# M261_v1 register map
File version: 1.0
Registers are 32-bit, read-write, reset 0x0 unless marked. A register's access mark holds for its fields unless they carry their own. Offsets are from the block's base; [hi:lo] are bit positions; {n}, {i} and the like mark numbered series; 'fields as' and 'values as' point back to an identical list.

## SYS — SYS Register Map
Base 0x40000000
0x00 SYS_PDID ro reset 0x235100 — Part Device Identification Number Register
  [31:0] PDID — Part Device Identification Number (Read Only). This register reflects device part number code. Software can read this register to identify which device is used.
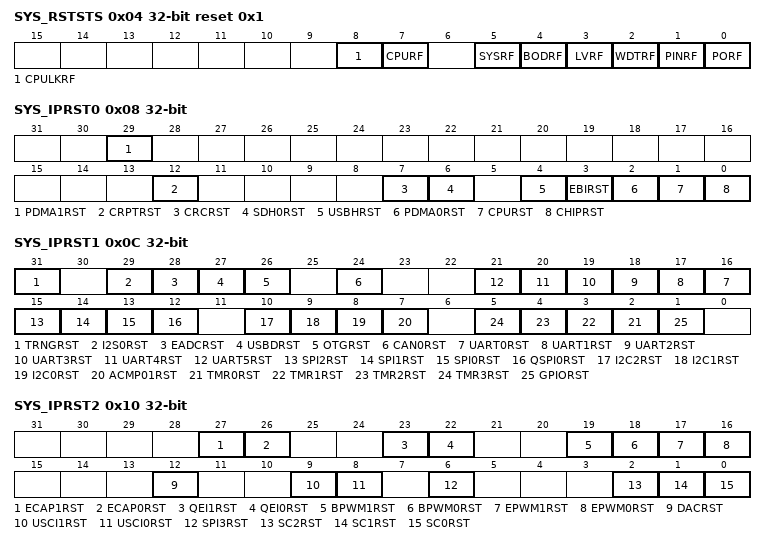
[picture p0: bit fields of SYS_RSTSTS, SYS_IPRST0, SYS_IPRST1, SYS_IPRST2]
0x04 SYS_RSTSTS reset 0x1 — System Reset Status Register
  [8] CPULKRF — CPU Lockup Reset Flag. The CPU Lockup reset flag is set by hardware if Cortex-M23 lockup happened. Note1: Write 1 to clear this bit to 0. Note2: When CPU lockup happened under ICE is connected, This flag will set to 1 but chip will not reset.
    0=No reset from CPU lockup happened; 1=The Cortex-M23 lockup happened and chip is reset
  [7] CPURF — CPU Reset Flag. The CPU reset flag is set by hardware if software writes CPURST (SYS_IPRST0[1]) 1 to reset the Cortex-M23 core and Flash Memory Controller (FMC). Note: Write 1 to clear this bit to 0.
    0=No reset from CPU; 1=The Cortex-M23 Core and FMC are reset by software setting CPURST to 1
  [5] SYSRF — System Reset Flag. The system reset flag is set by the 'Reset Signal' from the Cortex-M23 Core to indicate the previous reset source. Note: Write 1 to clear this bit to 0.
    0=No reset from the Cortex-M23; 1=The Cortex-M23 had issued the reset signal to reset the system by writing 1 to the bit SYSRESETREQ(AIRCR[2], Application Interrupt and Reset Control Register, address = 0xE000ED0C) in system control registers of Cortex-M23 core
  [4] BODRF — BOD Reset Flag. The BOD reset flag is set by the 'Reset Signal' from the Brown-out Detector to indicate the previous reset source. Note: Write 1 to clear this bit to 0.
    0=No reset from BOD; 1=The BOD had issued the reset signal to reset the system
  [3] LVRF — LVR Reset Flag. The LVR reset flag is set by the 'Reset Signal' from the Low Voltage Reset Controller to indicate the previous reset source. Note: Write 1 to clear this bit to 0.
    0=No reset from LVR; 1=LVR controller had issued the reset signal to reset the system
  [2] WDTRF — WDT Reset Flag. The WDT reset flag is set by the 'Reset Signal' from the Watchdog Timer or Window Watchdog Timer to indicate the previous reset source. Note1: Write 1 to clear this bit to 0. Note2: Watchdog Timer register RSTF(WDT_CTL[2]) bit is set if the system has been reset by WDT time-out reset. Window Watchdog Timer register WWDTRF(WWDT_STATUS[1]) bit is set if the system has been reset by WWDT time-out reset.
    0=No reset from watchdog timer or window watchdog timer; 1=The watchdog timer or window watchdog timer had issued the reset signal to reset the system
  [1] PINRF — nRESET Pin Reset Flag. The nRESET pin reset flag is set by the 'Reset Signal' from the nRESET Pin to indicate the previous reset source. Note: Write 1 to clear this bit to 0.
    0=No reset from nRESET pin; 1=Pin nRESET had issued the reset signal to reset the system
  [0] PORF — POR Reset Flag. The POR reset flag is set by the 'Reset Signal' from the Power-on Reset (POR) Controller or bit CHIPRST (SYS_IPRST0[0]) to indicate the previous reset source. Note: Write 1 to clear this bit to 0.
    0=No reset from POR or CHIPRST; 1=Power-on Reset (POR) or CHIPRST had issued the reset signal to reset the system
0x08 SYS_IPRST0 — Peripheral Reset Control Register 0
  [29] PDMA1RST — PDMA1 Controller Reset (Write Protect). Setting this bit to 1 will generate a reset signal to the PDMA1. User needs to set this bit to 0 to release from reset state. Note: This bit is write protected. Refer to the SYS_REGLCTL register.
    0=PDMA1 controller normal operation; 1=PDMA1 controller reset
  [12] CRPTRST — CRYPTO Controller Reset (Write Protect). Setting this bit to 1 will generate a reset signal to the CRYPTO controller. User needs to set this bit to 0 to release from the reset state. Note: This bit is write protected. Refer to the SYS_REGLCTL register.
    0=CRYPTO controller normal operation; 1=CRYPTO controller reset
  [7] CRCRST — CRC Calculation Controller Reset (Write Protect). Set this bit to 1 will generate a reset signal to the CRC calculation controller. User needs to set this bit to 0 to release from the reset state. Note: This bit is write protected. Refer to the SYS_REGLCTL register.
    0=CRC calculation controller normal operation; 1=CRC calculation controller reset
  [6] SDH0RST — SDHOST0 Controller Reset (Write Protect). Setting this bit to 1 will generate a reset signal to the SDHOST0 controller. User needs to set this bit to 0 to release from the reset state. Note: This bit is write protected. Refer to the SYS_REGLCTL register.
    0=SDHOST0 controller normal operation; 1=SDHOST0 controller reset
  [4] USBHRST — USB Host Controller Reset (Write Protect). Set this bit to 1 will generate a reset signal to the USB Host. User needs to set this bit to 0 to release from the reset state. Note: This bit is write protected. Refer to the SYS_REGLCTL register.
    0=USB Host controller normal operation; 1=USB Host controller reset
  [3] EBIRST — EBI Controller Reset (Write Protect). Set this bit to 1 will generate a reset signal to the EBI. User needs to set this bit to 0 to release from the reset state. Note: This bit is write protected. Refer to the SYS_REGLCTL register.
    0=EBI controller normal operation; 1=EBI controller reset
  [2] PDMA0RST — PDMA0 Controller Reset (Write Protect). Setting this bit to 1 will generate a reset signal to the PDMA0. User needs to set this bit to 0 to release from reset state. Note: This bit is write protected. Refer to the SYS_REGLCTL register.
    0=PDMA0 controller normal operation; 1=PDMA0 controller reset
  [1] CPURST — Processor Core One-shot Reset (Write Protect). Setting this bit will only reset the processor core and Flash Memory Controller(FMC), and this bit will automatically return to 0 after the 2 clock cycles. Note: This bit is write protected. Refer to the SYS_REGLCTL register.
    0=Processor core normal operation; 1=Processor core one-shot reset
  [0] CHIPRST — Chip One-shot Reset (Write Protect). Setting this bit will reset the whole chip, including Processor core and all peripherals, and this bit will automatically return to 0 after the 2 clock cycles. The CHIPRST is same as the POR reset, all the chip controllers is reset and the chip setting from Flash are also reload. About the difference between CHIPRST and SYSRESETREQ(AIRCR[2]), please refer to section 6.2.2. Note: This bit is write protected. Refer to the SYS_REGLCTL register.
    0=Chip normal operation; 1=Chip one-shot reset
0x0C SYS_IPRST1 — Peripheral Reset Control Register 1
  [31] TRNGRST — TRNG Controller Reset
    0=TRNG controller normal operation; 1=TRNG controller reset
  [29] I2S0RST — I2S0 Controller Reset
    0=I2S0 controller normal operation; 1=I2S0 controller reset
  [28] EADCRST — EADC Controller Reset
    0=EADC controller normal operation; 1=EADC controller reset
  [27] USBDRST — USBD Controller Reset
    0=USBD controller normal operation; 1=USBD controller reset
  [26] OTGRST — OTG Controller Reset
    0=OTG controller normal operation; 1=OTG controller reset
  [24] CAN0RST — CAN0 Controller Reset
    0=CAN0 controller normal operation; 1=CAN0 controller reset
  [n+16] UART{n}RST (n=0..5) — UART{n} Controller Reset
    0=UART{n} controller normal operation; 1=UART{n} controller reset
  [15] SPI2RST — SPI2 Controller Reset
    0=SPI2 controller normal operation; 1=SPI2 controller reset
  [14] SPI1RST — SPI1 Controller Reset
    0=SPI1 controller normal operation; 1=SPI1 controller reset
  [13] SPI0RST — SPI0 Controller Reset
    0=SPI0 controller normal operation; 1=SPI0 controller reset
  [12] QSPI0RST — QSPI0 Controller Reset
    0=QSPI0 controller normal operation; 1=QSPI0 controller reset
  [10] I2C2RST — I2C2 Controller Reset
    0=I2C2 controller normal operation; 1=I2C2 controller reset
  [9] I2C1RST — I2C1 Controller Reset
    0=I2C1 controller normal operation; 1=I2C1 controller reset
  [8] I2C0RST — I2C0 Controller Reset
    0=I2C0 controller normal operation; 1=I2C0 controller reset
  [7] ACMP01RST — Analog Comparator 0/1 Controller Reset
    0=Analog Comparator 0/1 controller normal operation; 1=Analog Comparator 0/1 controller reset
  [n+2] TMR{n}RST (n=0..3) — Timer{n} Controller Reset
    0=Timer{n} controller normal operation; 1=Timer{n} controller reset
  [1] GPIORST — GPIO Controller Reset
    0=GPIO controller normal operation; 1=GPIO controller reset
0x10 SYS_IPRST2 — Peripheral Reset Control Register 2
  [27] ECAP1RST — ECAP1 Controller Reset
    0=ECAP1 controller normal operation; 1=ECAP1 controller reset
  [26] ECAP0RST — ECAP0 Controller Reset
    0=ECAP0 controller normal operation; 1=ECAP0 controller reset
  [23] QEI1RST — QEI1 Controller Reset
    0=QEI1 controller normal operation; 1=QEI1 controller reset
  [22] QEI0RST — QEI0 Controller Reset
    0=QEI0 controller normal operation; 1=QEI0 controller reset
  [19] BPWM1RST — BPWM1 Controller Reset
    0=BPWM1 controller normal operation; 1=BPWM1 controller reset
  [18] BPWM0RST — BPWM0 Controller Reset
    0=BPWM0 controller normal operation; 1=BPWM0 controller reset
  [17] EPWM1RST — EPWM1 Controller Reset
    0=EPWM1 controller normal operation; 1=EPWM1 controller reset
  [16] EPWM0RST — EPWM0 Controller Reset
    0=EPWM0 controller normal operation; 1=EPWM0 controller reset
  [12] DACRST — DAC Controller Reset
    0=DAC controller normal operation; 1=DAC controller reset
  [9] USCI1RST — USCI1 Controller Reset
    0=USCI1 controller normal operation; 1=USCI1 controller reset
  [8] USCI0RST — USCI0 Controller Reset
    0=USCI0 controller normal operation; 1=USCI0 controller reset
  [6] SPI3RST — SPI3 Controller Reset
    0=SPI3 controller normal operation; 1=SPI3 controller reset
  [2] SC2RST — SC2 Controller Reset
    0=SC2 controller normal operation; 1=SC2 controller reset
  [1] SC1RST — SC1 Controller Reset
    0=SC1 controller normal operation; 1=SC1 controller reset
  [0] SC0RST — SC0 Controller Reset
    0=SC0 controller normal operation; 1=SC0 controller reset
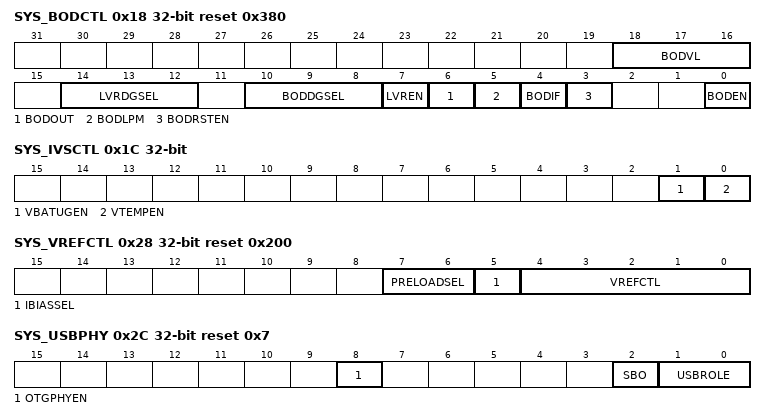
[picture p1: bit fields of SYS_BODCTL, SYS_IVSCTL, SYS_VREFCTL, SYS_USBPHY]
0x18 SYS_BODCTL reset 0x380 (reset mask 0xFFF0FFF0) — Brown-out Detector Control Register
  [18:16] BODVL — Brown-out Detector Threshold Voltage Selection (Write Protect). The default value is set by Flash controller user configuration register CBOV (CONFIG0 [23:21]). Note: These bits are write protected. Refer to the SYS_REGLCTL register.
    0=Brown-out Detector threshold voltage is 1.6V; 1=Brown-out Detector threshold voltage is 1.8V; 2=Brown-out Detector threshold voltage is 2.0V; 3=Brown-out Detector threshold voltage is 2.2V; 4=Brown-out Detector threshold voltage is 2.4V; 5=Brown-out Detector threshold voltage is 2.6V; 6=Brown-out Detector threshold voltage is 2.8V; 7=Brown-out Detector threshold voltage is 3.0V
  [14:12] LVRDGSEL — LVR Output De-glitch Time Select (Write Protect). Note: These bits are write protected. Refer to the SYS_REGLCTL register.
    0=Without de-glitch function; 1=4 system clock (HCLK); 2=8 system clock (HCLK); 3=16 system clock (HCLK); 4=32 system clock (HCLK); 5=64 system clock (HCLK); 6=128 system clock (HCLK); 7=256 system clock (HCLK)
  [10:8] BODDGSEL — Brown-out Detector Output De-glitch Time Select (Write Protect). Note: These bits are write protected. Refer to the SYS_REGLCTL register.
    0=BOD output is sampled by LIRC clock; 1=4 system clock (HCLK); 2=8 system clock (HCLK); 3=16 system clock (HCLK); 4=32 system clock (HCLK); 5=64 system clock (HCLK); 6=128 system clock (HCLK); 7=256 system clock (HCLK)
  [7] LVREN — Low Voltage Reset Enable Bit (Write Protect). The LVR function resets the chip when the input power voltage is lower than LVR circuit setting. LVR function is enabled by default. Note1: After enabling the bit, the LVR function will be active with 200us delay for LVR output stable (default). Note2: This bit is write protected. Refer to the SYS_REGLCTL register.
    0=Low Voltage Reset function Disabled; 1=Low Voltage Reset function Enabled
  [6] BODOUT — Brown-out Detector Output Status. It means the detected voltage is lower than BODVL setting. If the BODEN is 0, BOD function disabled, this bit always responds 0.
    0=Brown-out Detector output status is 0; 1=Brown-out Detector output status is 1
  [5] BODLPM — Brown-out Detector Low Power Mode (Write Protect). Note1: The BOD consumes about 100uA in normal mode, the low power mode can reduce the current to about 1/10 but slow the BOD response. Note2: This bit is write protected. Refer to the SYS_REGLCTL register.
    0=BOD operate in normal mode (default); 1=BOD Low Power mode Enabled
  [4] BODIF — Brown-out Detector Interrupt Flag. Note: Write 1 to clear this bit to 0.
    0=Brown-out Detector does not detect any voltage draft at VDD down through or up through the voltage of BODVL setting; 1=When Brown-out Detector detects the VDD is dropped down through the voltage of BODVL setting or the VDD is raised up through the voltage of BODVL setting, this bit is set to 1 and the brown-out interrupt is requested if brown-out interrupt is enabled
  [3] BODRSTEN — Brown-out Reset Enable Bit (Write Protect). The default value is set by Flash controller user configuration register CBORST(CONFIG0[20]) bit . Note1: While the Brown-out Detector function is enabled (BODEN high) and BOD reset function is enabled (BODRSTEN high), BOD will assert a signal to reset chip when the detected voltage is lower than the threshold (BODOUT high). While the BOD function is enabled (BODEN high) and BOD interrupt function is enabled (BODRSTEN low), BOD will assert an interrupt if AVDD.than BODVL, BOD interrupt will keep till to the BODIF set to 0. BOD interrupt can be blocked by disabling the NVIC BOD interrupt or disabling BOD function (set BODEN low). Note2: This bit is write protected. Refer to the SYS_REGLCTL register.
    0=Brown-out 'INTERRUPT' function Enabled; 1=Brown-out 'RESET' function Enabled
  [0] BODEN — Brown-out Detector Enable Bit (Write Protect). The default value is set by Flash controller user configuration register CBODEN (CONFIG0 [23]). Note: This bit is write protected. Refer to the SYS_REGLCTL register.
    0=Brown-out Detector function Disabled; 1=Brown-out Detector function Enabled
0x1C SYS_IVSCTL — Internal Voltage Source Control Register
  [1] VBATUGEN — VBAT Unity Gain Buffer Enable Bit. This bit is used to enable/disable VBAT unity gain buffer function. Note: After this bit is set to 1, the value of VBAT unity gain buffer output voltage can be obtained from ADC conversion result.
    0=VBAT unity gain buffer function Disabled (default); 1=VBAT unity gain buffer function Enabled
  [0] VTEMPEN — Temperature Sensor Enable Bit. This bit is used to enable/disable temperature sensor function. Note: After this bit is set to 1, the value of temperature sensor output can be obtained from ADC conversion result. Please refer to ADC function chapter for details.
    0=Temperature sensor function Disabled (default); 1=Temperature sensor function Enabled
0x24 SYS_PORCTL0 (reset mask 0xFFFFFF00) — Power-on Reset Controller Register 0
  [15:0] PORMASK — Power-on Reset Mask Enable Bit (Write Protect). When powered on, the POR circuit generates a reset signal to reset the whole chip function, but noise on the power may cause the POR active again. User can mask internal POR signal to avoid unpredictable noise to cause chip reset by writing 0x5AA5 to this field. The POR function will be active again when this field is set to another value or chip is reset by other reset source, including: nRESET, Watchdog, LVR reset, BOD reset, ICE reset command and the software-chip reset function. Note: These bits are write protected. Refer to the SYS_REGLCTL register.
0x28 SYS_VREFCTL reset 0x200 — VREF Control Register
  [7:6] PRELOADSEL — Pre-load Timing Selection (Write Protect). Note: These bits is write protected. Refer to the SYS_REGLCTL register.
    0=pre-load time is 60us for 0.1uF Capacitor; 1=pre-load time is 310us for 1uF Capacitor; 2=pre-load time is 2100us for 4.7uF Capacitor; 3=pre-load time is 2850us for 10uF Capacitor
  [5] IBIASSEL — VREF Bias Current Selection (Write Protect). Note: This bit is write protected. Refer to the SYS_REGLCTL register.
    0=Bias current from MEGBIAS; 1=Bias current from internal
  [4:0] VREFCTL — VREF Control Bits (Write Protect). Note: These bits are write protected. Refer to the SYS_REGLCTL register.
    0=VREF is from external pin; 3=VREF is internal 1.6V; 7=VREF is internal 2.0V; 11=VREF is internal 2.5V; 15=VREF is internal 3.0V
0x2C SYS_USBPHY reset 0x7 — USB PHY Control Register
  [8] OTGPHYEN — USB OTG PHY Enable. This bit is used to enable/disable OTG PHY function.
    0=OTG PHY function Disabled (default); 1=OTG PHY function Enabled
  [2] SBO — Note: This bit must always be kept 1. If set to 0, the result is unpredictable.
  [1:0] USBROLE — USB Role Option (Write Protect). These two bits are used to select the role of USB. Note: These bits are write protected. Refer to the SYS_REGLCTL register.
    0=Standard USB Device mode; 1=Standard USB Host mode; 2=ID dependent mode; 3=On-The-Go device mode (default)
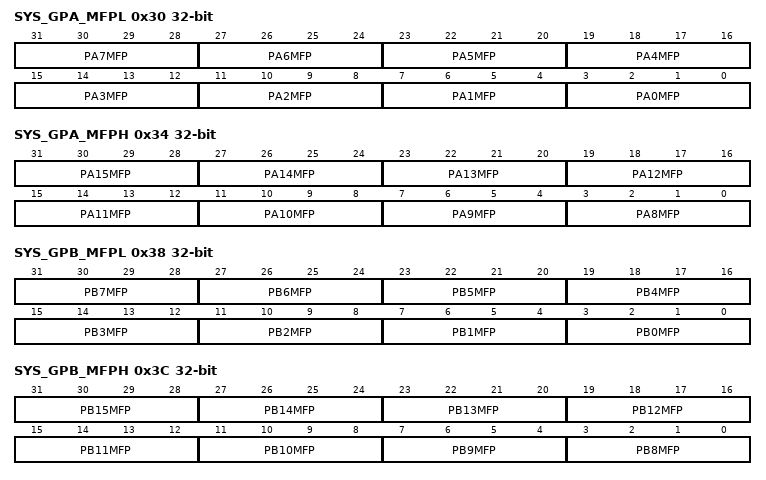
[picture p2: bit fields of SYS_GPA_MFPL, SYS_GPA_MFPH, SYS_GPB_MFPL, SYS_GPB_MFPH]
0x30 SYS_GPA_MFPL — GPIOA Low Byte Multiple Function Control Register
  [31:28] PA7MFP — PA.7 Multi-function Pin Selection
  [27:24] PA6MFP — PA.6 Multi-function Pin Selection
  [23:20] PA5MFP — PA.5 Multi-function Pin Selection
  [19:16] PA4MFP — PA.4 Multi-function Pin Selection
  [15:12] PA3MFP — PA.3 Multi-function Pin Selection
  [11:8] PA2MFP — PA.2 Multi-function Pin Selection
  [7:4] PA1MFP — PA.1 Multi-function Pin Selection
  [3:0] PA0MFP — PA.0 Multi-function Pin Selection
0x34 SYS_GPA_MFPH — GPIOA High Byte Multiple Function Control Register
  [31:28] PA15MFP — PA.15 Multi-function Pin Selection
  [27:24] PA14MFP — PA.14 Multi-function Pin Selection
  [23:20] PA13MFP — PA.13 Multi-function Pin Selection
  [19:16] PA12MFP — PA.12 Multi-function Pin Selection
  [15:12] PA11MFP — PA.11 Multi-function Pin Selection
  [11:8] PA10MFP — PA.10 Multi-function Pin Selection
  [7:4] PA9MFP — PA.9 Multi-function Pin Selection
  [3:0] PA8MFP — PA.8 Multi-function Pin Selection
0x38 SYS_GPB_MFPL — GPIOB Low Byte Multiple Function Control Register
  [31:28] PB7MFP — PB.7 Multi-function Pin Selection
  [27:24] PB6MFP — PB.6 Multi-function Pin Selection
  [23:20] PB5MFP — PB.5 Multi-function Pin Selection
  [19:16] PB4MFP — PB.4 Multi-function Pin Selection
  [15:12] PB3MFP — PB.3 Multi-function Pin Selection
  [11:8] PB2MFP — PB.2 Multi-function Pin Selection
  [7:4] PB1MFP — PB.1 Multi-function Pin Selection
  [3:0] PB0MFP — PB.0 Multi-function Pin Selection
0x3C SYS_GPB_MFPH — GPIOB High Byte Multiple Function Control Register
  [31:28] PB15MFP — PB.15 Multi-function Pin Selection
  [27:24] PB14MFP — PB.14 Multi-function Pin Selection
  [23:20] PB13MFP — PB.13 Multi-function Pin Selection
  [19:16] PB12MFP — PB.12 Multi-function Pin Selection
  [15:12] PB11MFP — PB.11 Multi-function Pin Selection
  [11:8] PB10MFP — PB.10 Multi-function Pin Selection
  [7:4] PB9MFP — PB.9 Multi-function Pin Selection
  [3:0] PB8MFP — PB.8 Multi-function Pin Selection
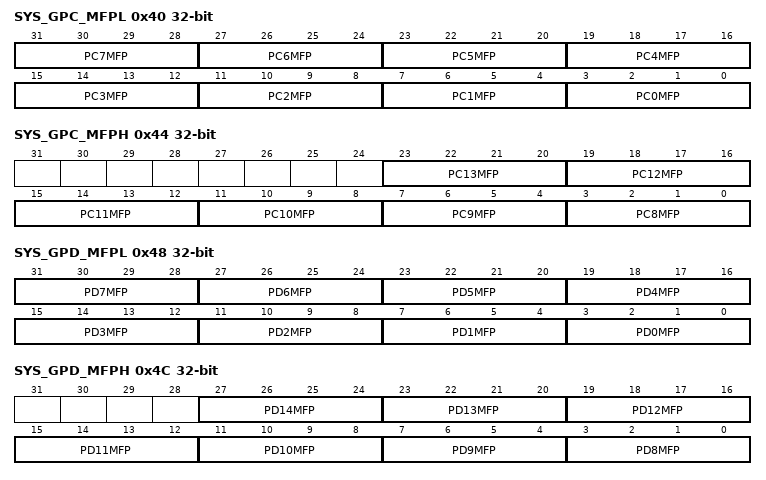
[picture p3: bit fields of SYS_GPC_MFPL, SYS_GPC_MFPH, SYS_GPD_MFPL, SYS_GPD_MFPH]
0x40 SYS_GPC_MFPL — GPIOC Low Byte Multiple Function Control Register
  [31:28] PC7MFP — PC.7 Multi-function Pin Selection
  [27:24] PC6MFP — PC.6 Multi-function Pin Selection
  [23:20] PC5MFP — PC.5 Multi-function Pin Selection
  [19:16] PC4MFP — PC.4 Multi-function Pin Selection
  [15:12] PC3MFP — PC.3 Multi-function Pin Selection
  [11:8] PC2MFP — PC.2 Multi-function Pin Selection
  [7:4] PC1MFP — PC.1 Multi-function Pin Selection
  [3:0] PC0MFP — PC.0 Multi-function Pin Selection
0x44 SYS_GPC_MFPH — GPIOC High Byte Multiple Function Control Register
  [23:20] PC13MFP — PC.13 Multi-function Pin Selection
  [19:16] PC12MFP — PC.12 Multi-function Pin Selection
  [15:12] PC11MFP — PC.11 Multi-function Pin Selection
  [11:8] PC10MFP — PC.10 Multi-function Pin Selection
  [7:4] PC9MFP — PC.9 Multi-function Pin Selection
  [3:0] PC8MFP — PC.8 Multi-function Pin Selection
0x48 SYS_GPD_MFPL — GPIOD Low Byte Multiple Function Control Register
  [31:28] PD7MFP — PD.7 Multi-function Pin Selection
  [27:24] PD6MFP — PD.6 Multi-function Pin Selection
  [23:20] PD5MFP — PD.5 Multi-function Pin Selection
  [19:16] PD4MFP — PD.4 Multi-function Pin Selection
  [15:12] PD3MFP — PD.3 Multi-function Pin Selection
  [11:8] PD2MFP — PD.2 Multi-function Pin Selection
  [7:4] PD1MFP — PD.1 Multi-function Pin Selection
  [3:0] PD0MFP — PD.0 Multi-function Pin Selection
0x4C SYS_GPD_MFPH — GPIOD High Byte Multiple Function Control Register
  [27:24] PD14MFP — PD.14 Multi-function Pin Selection
  [23:20] PD13MFP — PD.13 Multi-function Pin Selection
  [19:16] PD12MFP — PD.12 Multi-function Pin Selection
  [15:12] PD11MFP — PD.11 Multi-function Pin Selection
  [11:8] PD10MFP — PD.10 Multi-function Pin Selection
  [7:4] PD9MFP — PD.9 Multi-function Pin Selection
  [3:0] PD8MFP — PD.8 Multi-function Pin Selection
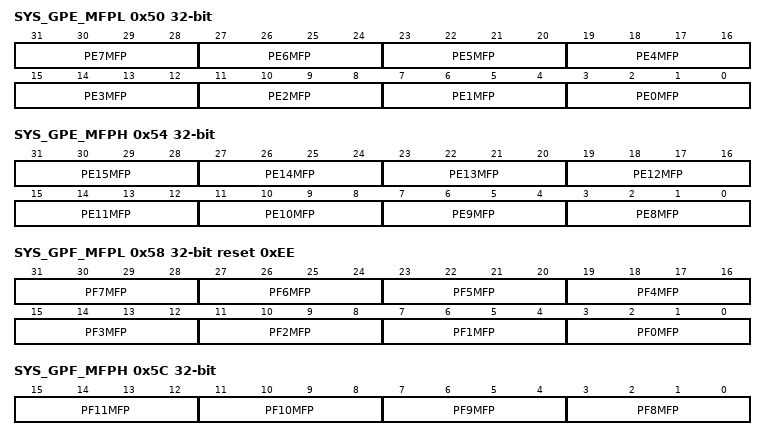
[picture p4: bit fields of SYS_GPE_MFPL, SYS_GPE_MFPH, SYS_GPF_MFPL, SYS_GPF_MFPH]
0x50 SYS_GPE_MFPL — GPIOE Low Byte Multiple Function Control Register
  [31:28] PE7MFP — PE.7 Multi-function Pin Selection
  [27:24] PE6MFP — PE.6 Multi-function Pin Selection
  [23:20] PE5MFP — PE.5 Multi-function Pin Selection
  [19:16] PE4MFP — PE.4 Multi-function Pin Selection
  [15:12] PE3MFP — PE.3 Multi-function Pin Selection
  [11:8] PE2MFP — PE.2 Multi-function Pin Selection
  [7:4] PE1MFP — PE.1 Multi-function Pin Selection
  [3:0] PE0MFP — PE.0 Multi-function Pin Selection
0x54 SYS_GPE_MFPH — GPIOE High Byte Multiple Function Control Register
  [31:28] PE15MFP — PE.15 Multi-function Pin Selection
  [27:24] PE14MFP — PE.14 Multi-function Pin Selection
  [23:20] PE13MFP — PE.13 Multi-function Pin Selection
  [19:16] PE12MFP — PE.12 Multi-function Pin Selection
  [15:12] PE11MFP — PE.11 Multi-function Pin Selection
  [11:8] PE10MFP — PE.10 Multi-function Pin Selection
  [7:4] PE9MFP — PE.9 Multi-function Pin Selection
  [3:0] PE8MFP — PE.8 Multi-function Pin Selection
0x58 SYS_GPF_MFPL reset 0xEE — GPIOF Low Byte Multiple Function Control Register
  [31:28] PF7MFP — PF.7 Multi-function Pin Selection
  [27:24] PF6MFP — PF.6 Multi-function Pin Selection
  [23:20] PF5MFP — PF.5 Multi-function Pin Selection
  [19:16] PF4MFP — PF.4 Multi-function Pin Selection
  [15:12] PF3MFP — PF.3 Multi-function Pin Selection
  [11:8] PF2MFP — PF.2 Multi-function Pin Selection
  [7:4] PF1MFP — PF.1 Multi-function Pin Selection
  [3:0] PF0MFP — PF.0 Multi-function Pin Selection
0x5C SYS_GPF_MFPH — GPIOF High Byte Multiple Function Control Register
  [15:12] PF11MFP — PF.11 Multi-function Pin Selection
  [11:8] PF10MFP — PF.10 Multi-function Pin Selection
  [7:4] PF9MFP — PF.9 Multi-function Pin Selection
  [3:0] PF8MFP — PF.8 Multi-function Pin Selection
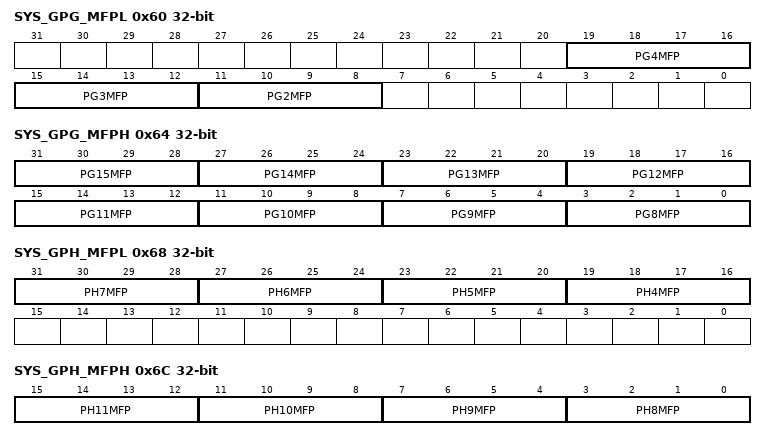
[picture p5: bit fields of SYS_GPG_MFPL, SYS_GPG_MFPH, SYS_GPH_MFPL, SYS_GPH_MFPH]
0x60 SYS_GPG_MFPL — GPIOG Low Byte Multiple Function Control Register
  [19:16] PG4MFP — PG.4 Multi-function Pin Selection
  [15:12] PG3MFP — PG.3 Multi-function Pin Selection
  [11:8] PG2MFP — PG.2 Multi-function Pin Selection
0x64 SYS_GPG_MFPH — GPIOG High Byte Multiple Function Control Register
  [31:28] PG15MFP — PG.15 Multi-function Pin Selection
  [27:24] PG14MFP — PG.14 Multi-function Pin Selection
  [23:20] PG13MFP — PG.13 Multi-function Pin Selection
  [19:16] PG12MFP — PG.12 Multi-function Pin Selection
  [15:12] PG11MFP — PG.11 Multi-function Pin Selection
  [11:8] PG10MFP — PG.10 Multi-function Pin Selection
  [7:4] PG9MFP — PG.9 Multi-function Pin Selection
  [3:0] PG8MFP — PG.8 Multi-function Pin Selection
0x68 SYS_GPH_MFPL — GPIOH Low Byte Multiple Function Control Register
  [31:28] PH7MFP — PH.7 Multi-function Pin Selection
  [27:24] PH6MFP — PH.6 Multi-function Pin Selection
  [23:20] PH5MFP — PH.5 Multi-function Pin Selection
  [19:16] PH4MFP — PH.4 Multi-function Pin Selection
0x6C SYS_GPH_MFPH — GPIOH High Byte Multiple Function Control Register
  [15:12] PH11MFP — PH.11 Multi-function Pin Selection
  [11:8] PH10MFP — PH.10 Multi-function Pin Selection
  [7:4] PH9MFP — PH.9 Multi-function Pin Selection
  [3:0] PH8MFP — PH.8 Multi-function Pin Selection
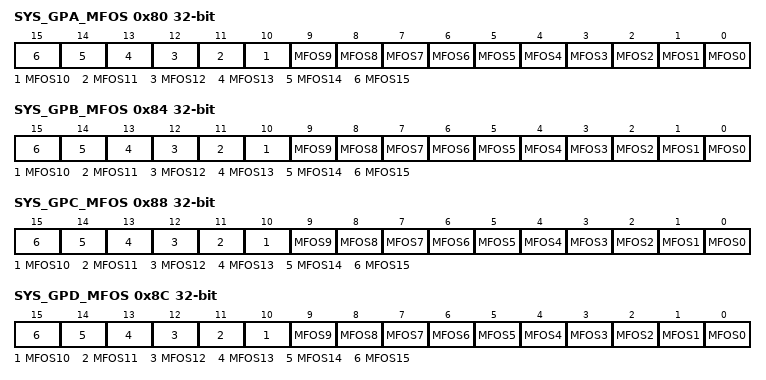
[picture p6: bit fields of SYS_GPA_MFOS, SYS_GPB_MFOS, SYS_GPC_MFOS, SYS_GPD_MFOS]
0x80 SYS_GPA_MFOS — GPIOA Multiple Function Output Select Register
  [all] fields
    0=Multiple funtion pin output mode type is Push-pull mode; 1=Multiple funtion pin output mode type is Open-drain mode
  [n] MFOS{n} (n=0..15) — GPIOA-h Pin[n] Multiple Function Pin Output Mode Select. This bit used to select multiple function pin output mode type for Px.n pin
0x84 SYS_GPB_MFOS — GPIOB Multiple Function Output Select Register
  fields as SYS_GPA_MFOS
0x88 SYS_GPC_MFOS — GPIOC Multiple Function Output Select Register
  fields as SYS_GPA_MFOS
0x8C SYS_GPD_MFOS — GPIOD Multiple Function Output Select Register
  fields as SYS_GPA_MFOS
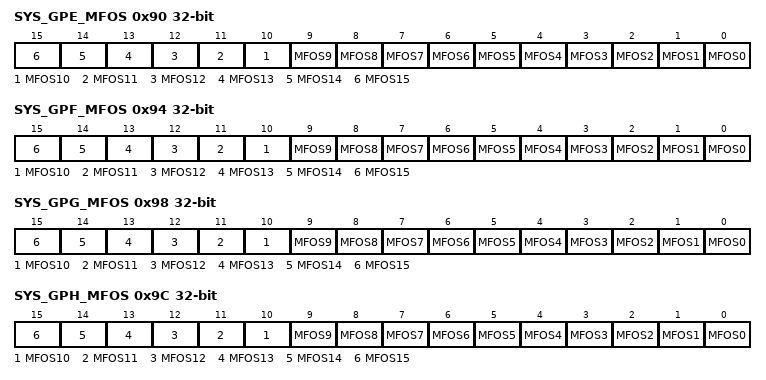
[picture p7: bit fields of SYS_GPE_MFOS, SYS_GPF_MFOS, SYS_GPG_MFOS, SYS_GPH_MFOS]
0x90 SYS_GPE_MFOS — GPIOE Multiple Function Output Select Register
  fields as SYS_GPA_MFOS
0x94 SYS_GPF_MFOS — GPIOF Multiple Function Output Select Register
  fields as SYS_GPA_MFOS
0x98 SYS_GPG_MFOS — GPIOG Multiple Function Output Select Register
  fields as SYS_GPA_MFOS
0x9C SYS_GPH_MFOS — GPIOH Multiple Function Output Select Register
  fields as SYS_GPA_MFOS
0xC0 SYS_SRAMICTL — System SRAM Interrupt Enable Control Register
  [0] PERRIEN — SRAM Parity Check Error Interrupt Enable Bit
    0=SRAM parity check error interrupt Disabled; 1=SRAM parity check error interrupt Enabled
0xC4 SYS_SRAMSTS ro — System SRAM Parity Error Status Register
  [0] PERRIF — SRAM Parity Check Error Flag. This bit indicates the System SRAM parity error occurred. Write 1 to clear this to 0.
    0=No System SRAM parity error; 1=System SRAM parity error occur
0xC8 SYS_SRAMEADR ro — System SRAM Parity Check Error Address Register
  [31:0] ERRADDR — System SRAM Parity Error Address. This register shows system SRAM parity error byte address.
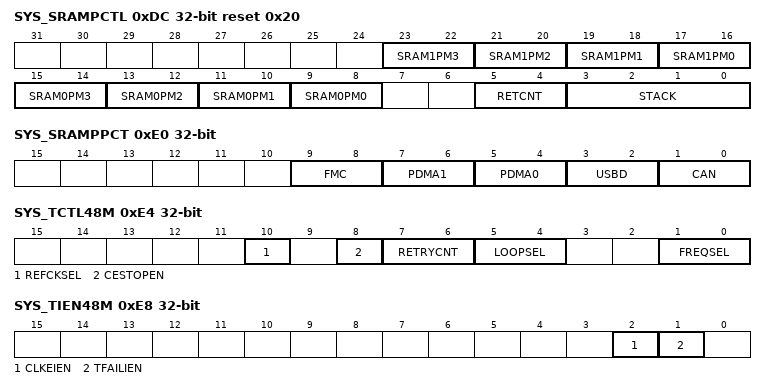
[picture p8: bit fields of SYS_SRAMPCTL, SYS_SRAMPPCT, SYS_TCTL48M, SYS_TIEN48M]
0xDC SYS_SRAMPCTL reset 0x20 — System SRAM Power Mode Control Register
  [23:22] SRAM1PM3 — Bank1 SRAM Power Mode Select 3 (Write Protect). This field can control bank1 SRAM (64 KB) power mode when system enters Power-down mode for range 0x2001_4000 - 0x2001_7FFF. Note1: Bank 1 SRAM is always operating in power shut down mode for system enter Standby Power-down Mode (SPD) and Deep Power-down Mode (DPD). Note2: These bits are write protected. Refer to the SYS_REGLCTL register.
    0=Normal mode; 1=Retention mode; 2=Power shut down mode
  [21:20] SRAM1PM2 — Bank1 SRAM Power Mode Select 2 (Write Protect). This field can control bank1 SRAM (64 KB) power mode when system enters Power-down mode for range 0x2001_0000 - 0x2001_3FFF. Note1: Bank 1 SRAM is always operating in power shut down mode for system enter Standby Power-down Mode (SPD) and Deep Power-down Mode (DPD). Note2: These bits are write protected. Refer to the SYS_REGLCTL register.
    0=Normal mode; 1=Retention mode; 2=Power shut down mode
  [19:18] SRAM1PM1 — Bank1 SRAM Power Mode Select 1 (Write Protect). This field can control bank1 SRAM (64 KB) power mode when system enters Power-down mode for range 0x2000_C000 - 0x2000_FFFF. Note1: Bank 1 SRAM is always operating in power shut down mode for system enter StandbyPower-down Mode (SPD) and Deep Power-down Mode (DPD). Note2: These bits are write protected. Refer to the SYS_REGLCTL register.
    0=Normal mode; 1=Retention mode; 2=Power shut down mode
  [17:16] SRAM1PM0 — Bank1 SRAM Power Mode Select 0 (Write Protect). This field can control bank1 SRAM (64 KB) power mode when system enters Power-down mode for range 0x2000_8000 - 0x2000_BFFF. Note1: Bank 1 SRAM is always operating in power shut down mode for system enter StandbyPower-down Mode (SPD) and Deep Power-down Mode (DPD). Note2: These bits are write protected. Refer to the SYS_REGLCTL register.
    0=Normal mode; 1=Retention mode; 2=Power shut down mode
  [15:14] SRAM0PM3 — Bank0 SRAM Power Mode Select 3 (Write Protect). This field can control bank0 SRAM (32 KB) power mode when system enters Power-down mode for range 0x2006_0000 - 0x2000_7FFF. Note1: Bank 0 SRAM is always operating in power shut down mode for system enter Deep Power-down Mode (DPD). Note2: These bits are write protected. Refer to the SYS_REGLCTL register.
    0=Normal mode; 1=Retention mode; 2=Power shut down mode
  [13:12] SRAM0PM2 — Bank0 SRAM Power Mode Select 2 (Write Protect). This field can control bank0 SRAM (32 KB) power mode when system enters Power-down mode for range 0x2004_0000 - 0x2000_5FFF. Note1: Bank 0 SRAM is always operating in power shut down mode for system enter Deep Power-down Mode (DPD). Note2: These bits are write protected. Refer to the SYS_REGLCTL register.
    0=Normal mode; 1=Retention mode; 2=Power shut down mode
  [11:10] SRAM0PM1 — Bank0 SRAM Power Mode Select 1 (Write Protect). This field can control bank0 sram (32k) power mode when system enters Power-down mode for range 0x2000_2000 - 0x2000_3FFF. Note1: Bank 0 SRAM is always operating in power shut down mode for system enter Deep Power-down Mode (DPD). Note2: These bits are write protected. Refer to the SYS_REGLCTL register.
    0=Normal mode; 1=Retention mode; 2=Power shut down mode
  [9:8] SRAM0PM0 — Bank0 SRAM Power Mode Select 0 (Write Protect). This field can control bank0 SRAM (32 KB) power mode when system enters Power-down mode for range 0x2000_0000 - 0x2000_1FFF. Note1: Bank 0 SRAM is always operating in power shut down mode for system enter Deep Power-down Mode (DPD). Note2: These bits are write protected. Refer to the SYS_REGLCTL register.
    0=Normal mode; 1=Retention mode; 2=Power shut down mode
  [5:4] RETCNT — SRAM Retention Count (Write Protect). This field can configure SRAM marco retention time in unit of HIRC period. Note: These bits are write protected. Refer to the SYS_REGLCTL register.
    0=one HIRC period; 1=two HIRC periods; 2=three HIRC periods; 3=four HIRC periods
  [3:0] STACK — System SRAM Stack Position (Write Protect). This field must configure the system SRAM marco that first SRAM address accessed by CPU in power-on process. Note: These bits are write protected. Refer to the SYS_REGLCTL register.
0xE0 SYS_SRAMPPCT — Peripheral SRAM Power Mode Control Register
  [all] fields
    0=Normal mode; 1=Retention mode; 2=Power shut down mode
  [9:8] FMC — FMC SRAM Power Mode Select (Write Protect). This field can control FMC cache SRAM power mode for system enter Power-down mode. Note1: Peripheral SRAM is always operating in power shut down mode for system enter Standby Power-down Mode (SPD) and Deep Power-down Mode (DPD). Note2: These bits are write protected. Refer to the SYS_REGLCTL register.
  [7:6] PDMA1 — PDMA SRAM Power Mode Select (Write Protect). This field can control PDMA1 SRAM power mode for system enter Power-down mode. Note1: Peripheral SRAM is always operating in power shut down mode for system enter Standby Power-down Mode (SPD) and Deep Power-down Mode (DPD). Note2: These bits are write protected. Refer to the SYS_REGLCTL register.
  [5:4] PDMA0 — PDMA SRAM Power Mode Select (Write Protect). This field can control PDMA0 SRAM power mode for system enter Power-down mode. Note1: Peripheral SRAM is always operating in power shut down mode for system enter Standby Power-down Mode (SPD) and Deep Power-down Mode (DPD). Note2: These bits are write protected. Refer to the SYS_REGLCTL register.
  [3:2] USBD — USB Device SRAM Power Mode Select (Write Protect). This field can control USB device SRAM power mode for system enter Power-down mode. Note1: Peripheral SRAM is always operating in power shut down mode for system enter Standby Power-down Mode (SPD) and Deep Power-down Mode (DPD). Note2: These bits are write protected. Refer to the SYS_REGLCTL register.
  [1:0] CAN — CAN SRAM Power Mode Select (Write Protect). This field can control CAN SRAM power mode for system enter Power-down mode. Note1: Peripheral SRAM is always operating in power shut down mode for system enter Standby Power-down Mode (SPD) and Deep Power-down Mode (DPD). Note2: These bits are write protected. Refer to the SYS_REGLCTL register.
0xE4 SYS_TCTL48M — HIRC 48M Trim Control Register
  [10] REFCKSEL — Reference Clock Selection
    0=HIRC trim 48M reference clock is from external 32.768 kHz crystal oscillator; 1=HIRC trim 48M reference clock is from internal USB synchronous mode
  [8] CESTOPEN — Clock Error Stop Enable Bit
    0=The trim operation is keep going if clock is inaccuracy; 1=The trim operation is stopped if clock is inaccuracy
  [7:6] RETRYCNT — Trim Value Update Limitation Count. This field defines that how many times the auto trim circuit will try to update the HIRC trim value before the frequency of HIRC locked. Once the HIRC locked, the internal trim value update counter will be reset. If the trim value update counter reached this limitation value and frequency of HIRC still doesn't lock, the auto trim operation will be disabled and FREQSEL will be cleared to 00.
    0=Trim retry count limitation is 64 loops; 1=Trim retry count limitation is 128 loops; 2=Trim retry count limitation is 256 loops; 3=Trim retry count limitation is 512 loops
  [5:4] LOOPSEL — Trim Calculation Loop Selection. This field defines that trim value calculation is based on how many reference clocks. Note: For example, if LOOPSEL is set as 00, auto trim circuit will calculate trim value based on the average frequency difference in 4 clocks of reference clock.
    0=Trim value calculation is based on average difference in 4 clocks of reference clock; 1=Trim value calculation is based on average difference in 8 clocks of reference clock; 2=Trim value calculation is based on average difference in 16 clocks of reference clock; 3=Trim value calculation is based on average difference in 32 clocks of reference clock
  [1:0] FREQSEL — Trim Frequency Selection. This field indicates the target frequency of 48 MHz internal high speed RC oscillator (HIRC) auto trim. During auto trim operation, if clock error detected with CESTOPEN is set to 1 or trim retry limitation count reached, this field will be cleared to 00 automatically.
    0=Disable HIRC auto trim function; 1=Enable HIRC auto trim function and trim HIRC to 48 MHz
0xE8 SYS_TIEN48M — HIRC 48M Trim Interrupt Enable Register
  [2] CLKEIEN — Clock Error Interrupt Enable Bit. This bit controls if CPU would get an interrupt while clock is inaccuracy during auto trim operation. If this bit is set to1, and CLKERRIF(SYS_TISTS48M [2]) is set during auto trim operation, an interrupt will be triggered to notify the clock frequency is inaccuracy.
    0=Disable CLKERRIF(SYS_TISTS48M [2]) status to trigger an interrupt to CPU; 1=Enable CLKERRIF(SYS_TISTS48M [2]) status to trigger an interrupt to CPU
  [1] TFAILIEN — Trim Failure Interrupt Enable Bit. This bit controls if an interrupt will be triggered while HIRC trim value update limitation count reached and HIRC frequency still not locked on target frequency set by FREQSEL(SYS_TCTL48M[1:0]). If this bit is high and TFAILIF(SYS_TSTS48M [1]) is set during auto trim operation, an interrupt will be triggered to notify that HIRC trim value update limitation count was reached.
    0=Disable TFAILIF(SYS_TISTS48M [1]) status to trigger an interrupt to CPU; 1=Enable TFAILIF(SYS_TISTS48M[1]) status to trigger an interrupt to CPU
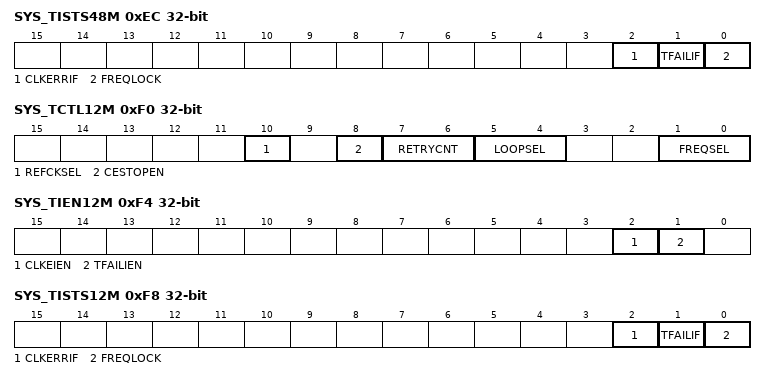
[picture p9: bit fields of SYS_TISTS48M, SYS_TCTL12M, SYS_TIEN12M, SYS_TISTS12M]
0xEC SYS_TISTS48M — HIRC 48M Trim Interrupt Status Register
  [2] CLKERRIF — Clock Error Interrupt Status. When the frequency of 32.768 kHz external low speed crystal oscillator (LXT) or 48MHz internal high speed RC oscillator (HIRC) is shift larger to unreasonable value, this bit will be set and to be an indicate that clock frequency is inaccuracy. Once this bit is set to 1, the auto trim operation stopped and FREQSEL(SYS_TCTL48M[1:0]) will be cleared to 00 by hardware automatically if CESTOPEN(SYS_TCTL48M[8]) is set to 1. If this bit is set and CLKEIEN(SYS_TIEN48M[2]) is high, an interrupt will be triggered to notify the clock frequency is inaccuracy. Write 1 to clear this to 0.
    0=Clock frequency is accuracy; 1=Clock frequency is inaccuracy
  [1] TFAILIF — Trim Failure Interrupt Status. This bit indicates that HIRC trim value update limitation count reached and the HIRC clock frequency still doesn't be locked. Once this bit is set, the auto trim operation stopped and FREQSEL(SYS_TCTL48M[1:0]) will be cleared to 00 by hardware automatically. If this bit is set and TFAILIEN(SYS_TIEN48M[1]) is high, an interrupt will be triggered to notify that HIRC trim value update limitation count was reached. Write 1 to clear this to 0.
    0=Trim value update limitation count does not reach; 1=Trim value update limitation count reached and HIRC frequency still not locked
  [0] FREQLOCK — HIRC Frequency Lock Status. This bit indicates the HIRC frequency is locked. This is a status bit and doesn't trigger any interrupt. Write 1 to clear this to 0. This bit will be set automatically, if the frequecy is lock and the RC_TRIM is enabled.
    0=The internal high-speed oscillator frequency doesn't lock at 48 MHz yet; 1=The internal high-speed oscillator frequency locked at 48 MHz
0xF0 SYS_TCTL12M — HIRC 12M Trim Control Register
  [10] REFCKSEL — Reference Clock Selection
    0=HIRC trim reference clock is from external 32.768 kHz crystal oscillator; 1=HIRC trim reference clock is from internal USB synchronous mode
  [8] CESTOPEN — Clock Error Stop Enable Bit
    values as SYS_TCTL48M.CESTOPEN
  [7:6] RETRYCNT — Trim Value Update Limitation Count. This field defines that how many times the auto trim circuit will try to update the HIRC trim value before the frequency of HIRC locked. Once the HIRC locked, the internal trim value update counter will be reset. If the trim value update counter reached this limitation value and frequency of HIRC still doesn't lock, the auto trim operation will be disabled and FREQSEL will be cleared to 00.
    values as SYS_TCTL48M.RETRYCNT
  [5:4] LOOPSEL — Trim Calculation Loop Selection. This field defines that trim value calculation is based on how many reference clocks. Note: For example, if LOOPSEL is set as 00, auto trim circuit will calculate trim value based on the average frequency difference in 4 clocks of reference clock.
    values as SYS_TCTL48M.LOOPSEL
  [1:0] FREQSEL — Trim Frequency Selection. This field indicates the target frequency of 12 MHz internal high speed RC oscillator (HIRC) auto trim. During auto trim operation, if clock error detected with CESTOPEN is set to 1 or trim retry limitation count reached, this field will be cleared to 00 automatically.
    0=Disable HIRC auto trim function; 1=Enable HIRC auto trim function and trim HIRC to 12 MHz
0xF4 SYS_TIEN12M — HIRC 12M Trim Interrupt Enable Register
  [2] CLKEIEN — Clock Error Interrupt Enable Bit. This bit controls if CPU would get an interrupt while clock is inaccuracy during auto trim operation. If this bit is set to1, and CLKERRIF(SYS_TISTS12M[2]) is set during auto trim operation, an interrupt will be triggered to notify the clock frequency is inaccuracy.
    0=Disable CLKERRIF(SYS_TISTS12M[2]) status to trigger an interrupt to CPU; 1=Enable CLKERRIF(SYS_TISTS12M[2]) status to trigger an interrupt to CPU
  [1] TFAILIEN — Trim Failure Interrupt Enable Bit. This bit controls if an interrupt will be triggered while HIRC trim value update limitation count reached and HIRC frequency still not locked on target frequency set by FREQSEL(SYS_TCTL12M[1:0]). If this bit is high and TFAILIF(SYS_TSTS12M[1]) is set during auto trim operation, an interrupt will be triggered to notify that HIRC trim value update limitation count was reached.
    0=Disable TFAILIF(SYS_TISTS12M[1]) status to trigger an interrupt to CPU; 1=Enable TFAILIF(SYS_TISTS12M[1]) status to trigger an interrupt to CPU
0xF8 SYS_TISTS12M — HIRC 12M Trim Interrupt Status Register
  [2] CLKERRIF — Clock Error Interrupt Status. When the frequency of 32.768 kHz external low speed crystal oscillator (LXT) or 12MHz internal high speed RC oscillator (HIRC) is shift larger to unreasonable value, this bit will be set and to be an indicate that clock frequency is inaccuracy. Once this bit is set to 1, the auto trim operation stopped and FREQSEL(SYS_TCTL12M[1:0]) will be cleared to 00 by hardware automatically if CESTOPEN(SYS_TCTL12M[8]) is set to 1. If this bit is set and CLKEIEN(SYS_IRCTIEN[2]) is high, an interrupt will be triggered to notify the clock frequency is inaccuracy. Write 1 to clear this to 0.
    values as SYS_TISTS48M.CLKERRIF
  [1] TFAILIF — Trim Failure Interrupt Status. This bit indicates that HIRC trim value update limitation count reached and the HIRC clock frequency still doesn't be locked. Once this bit is set, the auto trim operation stopped and FREQSEL(SYS_TCTL12M[1:0]) will be cleared to 00 by hardware automatically. If this bit is set and TFAILIEN(SYS_TIEN12M[1]) is high, an interrupt will be triggered to notify that HIRC trim value update limitation count was reached. Write 1 to clear this to 0.
    values as SYS_TISTS48M.TFAILIF
  [0] FREQLOCK — HIRC Frequency Lock Status. This bit indicates the HIRC frequency is locked. This is a status bit and doesn't trigger any interrupt. Write 1 to clear this to 0. This bit will be set automatically, if the frequecy is lock and the RC_TRIM is enabled.
    0=The internal high-speed oscillator frequency doesn't lock at 12 MHz yet; 1=The internal high-speed oscillator frequency locked at 12 MHz
0x100 SYS_REGLCTL — Register Lock Control Register
  [7:0] REGLCTL — Register Lock Control Code. Some registers have write-protection function. Writing these registers have to disable the protected function by writing the sequence value '59h', '16h', '88h' to this field. After this sequence is completed, the REGLCTL bit will be set to 1 and write-protection registers can be normal write. . REGLCTL[0]. Register Lock Control Disable Index
    0=Write-protection Enabled for writing protected registers. Any write to the protected register is ignored; 1=Write-protection Disabled for writing protected registers
0x1EC SYS_PORCTL1 (reset mask 0xFFFFFF00) — Power-on Reset Controller Register 1
  [15:0] POROFF — Power-on Reset Enable Bit (Write Protect). When powered on, the POR circuit generates a reset signal to reset the whole chip function, but noise on the power may cause the POR active again. User can disable internal POR circuit to avoid unpredictable noise to cause chip reset by writing 0x5AA5 to this field. The POR function will be active again when this field is set to another value or chip is reset by other reset source, including: nRESET, Watchdog, LVR reset, BOD reset, ICE reset command and the software-chip reset function. Note: These bits are write protected. Refer to the SYS_REGLCTL register.
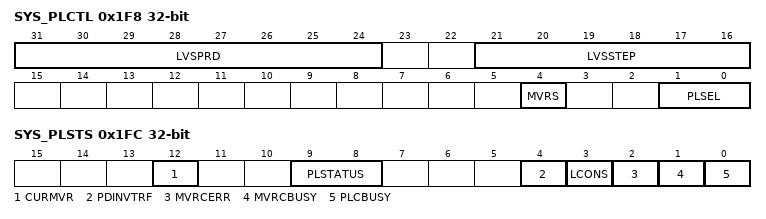
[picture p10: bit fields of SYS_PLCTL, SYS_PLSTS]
0x1F8 SYS_PLCTL — Power Level Control Register
  [31:24] LVSPRD — LDO Voltage Scaling Period (Write Protect). The LVSPRD value is the period of each LDO voltage rising step. Note: These bits are write protected. Refer to the SYS_REGLCTL register.
  [21:16] LVSSTEP — LDO Voltage Scaling Step (Write Protect). The LVSSTEP value is LDO voltage rising step. Note: These bits are write protected. Refer to the SYS_REGLCTL register.
  [4] MVRS — Main Voltage Regulator Type Select (Write Protect). This bit filed sets main voltage regulator type. Note: This bit is write protected. Refer to the SYS_REGLCTL register.
    0=Set main voltage regulator to LDO; 1=Set main voltage regulator to DCDC
  [1:0] PLSEL — Power Level Select (Write Protect). Note: These bits are write protected. Refer to the SYS_REGLCTL register.
    0=Set to Power level 0 (PL0); 1=Set to Power level 1 (PL1)
0x1FC SYS_PLSTS (reset mask 0xFFFFFFF0) — Power Level Status Register
  [12] CURMVR ro — Current Main Voltage Regulator Type (Read Only). This bit field reflects current main voltage regulator type.
    0=Current main voltage regulator in active and Idle mode is LDO; 1=Current main voltage regulator in active mode and Idle is DCDC
  [9:8] PLSTATUS ro — Power Level Status (Read Only). This bit field reflect the current power level.
    0=Power level is PL0; 1=Power level is PL1
  [4] PDINVTRF — Power-down Mode Invalid Transition Flag (Write Protect). This bit is set by hardware if the requested active DCDC mode to Power-down mode transition is invalid. This transition request will be aborted by hardware. The bit can be cleared by software. Read: Note: This bit is write protected. Refer to the SYS_REGLCTL register.
    0=No Power-dwon mode invalid transition. No effect; 1=Power-dwon mode invalid transition occurred. Clears this bit to 0
  [3] LCONS ro — Inductor for DC-dC Connect Status (Read Only). Note: This bit is 1 when main viltage regulator is LDO.
    0=Inductor connect between Vsw and LDO_CAP pin; 1=No Inductor connect between Vsw and LDO_CAP pin
  [2] MVRCERR — Main Voltage Regulator Type Change Error Bit (Write Protect). This bit Is set by Hardware When Main Voltage Regulator Type Change From LDO to DCDC Error Occurred. This bit is set to 1 when main voltage regulator type change from LDO to DCDC error, the following conditions will cause change errors. 1.System change to DC-DC mode but LDO change voltage process not finish. 2.Detect inductor fail. . Note: This bit is write protected. Refer to the SYS_REGLCTL register.
    0=No main voltage regulator type change error. No effect; 1=Main voltage regulator type change to DCDC error occurred. Clears MVRCERR to 0
  [1] MVRCBUSY ro — Main Voltage Regulator Type Change Busy Bit (Read Only). This bit is set by hardware when main voltage regulator type is changing. After main voltage regulator type change is completed, this bit will be cleared automatically by hardware.
    0=Main voltage regulator type change is completed; 1=Main voltage regulator type change is ongoing
  [0] PLCBUSY ro — Power Level Change Busy Bit (Read Only). This bit is set by hardware when power level is changing . After power level change is completed, this bit will be cleared automatically by hardware.
    0=Power level change is completed; 1=Power level change is ongoing
